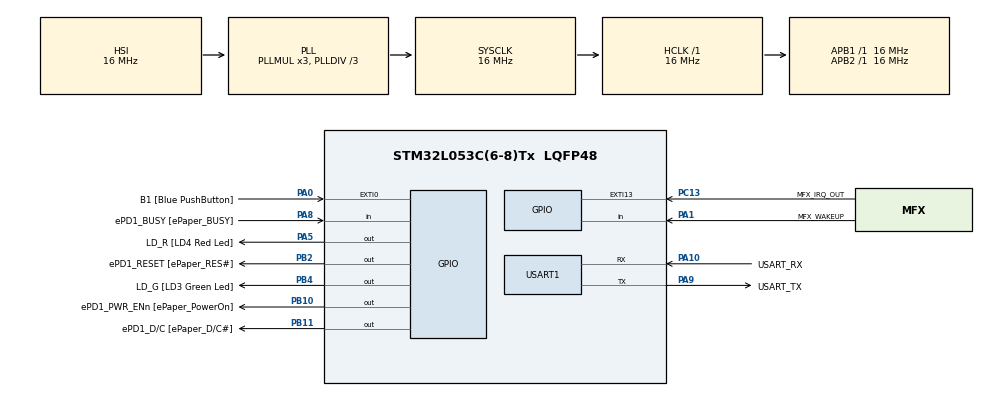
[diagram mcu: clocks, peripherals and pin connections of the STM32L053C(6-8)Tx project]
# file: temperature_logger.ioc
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Mcu.Family=STM32L0
Mcu.Name=STM32L053C(6-8)Tx
Mcu.Package=LQFP48
NVIC.RTC_IRQn=true\:0\:0\:false\:false\:true\:true
PA0.GPIO_Label=B1 [Blue PushButton]
PA0.GPIO_ModeDefaultEXTI=GPIO_MODE_EVT_RISING
PA0.GPIO_PuPd=GPIO_NOPULL
PA0.Signal=GPXTI0
PA1.GPIO_Label=MFX_WAKEUP
PA1.Signal=GPIO_Input
PA10.GPIO_Label=USART_RX
PA10.Mode=Asynchronous
PA10.Signal=USART1_RX
PA11.GPIO_Label=USB1_DM
PA11.Signal=USB_DM
PA12.GPIO_Label=USB1_DP
PA12.Signal=USB_DP
PA13.GPIO_Label=SWDIO
PA13.Signal=SYS_SWDIO
PA15.GPIO_Label=ePD1_CS [ePaper_CS\#]
PA15.GPIO_Mode=GPIO_MODE_AF_PP
PA15.GPIO_PuPd=GPIO_NOPULL
PA15.GPIO_Speed=GPIO_SPEED_FREQ_LOW
PA15.Signal=SPI1_NSS
PA2.Signal=TSC_G1_IO3
PA3.Signal=TSC_G1_IO4
PA5.GPIO_Label=LD_R [LD4 Red Led]
PA5.GPIO_ModeDefaultOutputPP=GPIO_MODE_OUTPUT_PP
PA5.GPIO_PuPd=GPIO_NOPULL
PA5.GPIO_Speed=GPIO_SPEED_FREQ_LOW
PA5.Signal=GPIO_Output
PA6.Signal=TSC_G2_IO3
PA7.Signal=TSC_G2_IO4
PA8.GPIO_Label=ePD1_BUSY [ePaper_BUSY]
PA8.GPIO_Mode=GPIO_MODE_INPUT
PA8.GPIO_PuPd=GPIO_NOPULL
PA8.Signal=GPIO_Input
PA9.GPIO_Label=USART_TX
PA9.Mode=Asynchronous
PA9.Signal=USART1_TX
PB0.Signal=TSC_G3_IO2
PB1.Signal=TSC_G3_IO3
PB10.GPIO_Label=ePD1_PWR_ENn [ePaper_PowerOn]
PB10.GPIO_ModeDefaultOutputPP=GPIO_MODE_OUTPUT_PP
PB10.GPIO_PuPd=GPIO_NOPULL
PB10.GPIO_Speed=GPIO_SPEED_FREQ_LOW
PB10.Signal=GPIO_Output
PB11.GPIO_Label=ePD1_D/C [ePaper_D/C\#]
PB11.GPIO_ModeDefaultOutputPP=GPIO_MODE_OUTPUT_PP
PB11.GPIO_PuPd=GPIO_NOPULL
PB11.GPIO_Speed=GPIO_SPEED_FREQ_LOW
PB11.Signal=GPIO_Output
PB12.GPIO_Label=NFC_NSS
PB12.Signal=SPI2_NSS
PB13.GPIO_Label=NFC_SCK
PB13.Signal=SPI2_SCK
PB14.GPIO_Label=NFC_MISO
PB14.Signal=SPI2_MISO
PB15.GPIO_Label=NFC_MOSI
PB15.Signal=SPI2_MOSI
PB2.GPIO_Label=ePD1_RESET [ePaper_RES\#]
PB2.GPIO_ModeDefaultOutputPP=GPIO_MODE_OUTPUT_PP
PB2.GPIO_PuPd=GPIO_NOPULL
PB2.GPIO_Speed=GPIO_SPEED_FREQ_LOW
PB2.Signal=GPIO_Output
PB3.GPIO_Label=ePD1_SCK [ePaper_SCK]
PB3.GPIO_Mode=GPIO_MODE_AF_PP
PB3.GPIO_PuPd=GPIO_NOPULL
PB3.GPIO_Speed=GPIO_SPEED_FREQ_LOW
PB3.Signal=SPI1_SCK
PB4.GPIO_Label=LD_G [LD3 Green Led]
PB4.GPIO_ModeDefaultOutputPP=GPIO_MODE_OUTPUT_PP
PB4.GPIO_PuPd=GPIO_NOPULL
PB4.GPIO_Speed=GPIO_SPEED_FREQ_LOW
PB4.Signal=GPIO_Output
PB5.GPIO_Label=ePD1_MOSI [ePaper_MOSI]
PB5.GPIO_Mode=GPIO_MODE_AF_PP
PB5.GPIO_PuPd=GPIO_NOPULL
PB5.GPIO_Speed=GPIO_SPEED_FREQ_LOW
PB5.Signal=SPI1_MOSI
PB8.GPIO_Label=MFX_I2C_SCL
PB8.Signal=I2C1_SCL
PB9.GPIO_Label=MFX_I2C_SDA
PB9.Signal=I2C1_SDA
PC13.GPIO_Label=MFX_IRQ_OUT
PC13.Signal=GPXTI13
PC14-OSC32_IN.GPIO_Label=PC14-OSC32_IN
PC14-OSC32_IN.Signal=RCC_OSC32_IN
PC15-OSC32_OUT.GPIO_Label=PC15-OSC32_OUT
PC15-OSC32_OUT.Signal=RCC_OSC32_OUT
PH0-OSC_IN.GPIO_Label=MCO
PH0-OSC_IN.Signal=RCC_OSC_IN
ProjectManager.HeapSize=0x200
ProjectManager.StackSize=0x400
ProjectManager.TargetToolchain=SW4STM32
RCC.AHBFreq_Value=16000000
RCC.APB1Freq_Value=16000000
RCC.APB1TimFreq_Value=16000000
RCC.APB2Freq_Value=16000000
RCC.APB2TimFreq_Value=16000000
RCC.HCLKFreq_Value=16000000
RCC.HSE_VALUE=8000000
RCC.HSI16_VALUE=16000000
RCC.HSI48MClockSelection=RCC_USBCLKSOURCE_HSI48
RCC.HSI48_VALUE=48000000
RCC.HSI_VALUE=16000000
RCC.LSE_VALUE=32768
RCC.MSI_VALUE=2097000
RCC.PLLDIV=RCC_PLLDIV_3
RCC.RTCClockSelection=RCC_RTCCLKSOURCE_LSI
RCC.RTCClockSelectionVirtual=RCC_RTCCLKSOURCE_LSE
RCC.SYSCLKFreq_VALUE=16000000
RCC.SYSCLKSource=RCC_SYSCLKSOURCE_PLLCLK
RCC.VCOOutputFreq_Value=48000000
RTC.Alarm-Alarm\ A=RTC_ALARM_A
RTC.AlarmMaskDateWeekDay-Alarm\ A=RTC_ALARMMASK_DATEWEEKDAY
RTC.AsynchPrediv=100
RTC.Date=26
RTC.Format=RTC_FORMAT_BIN
RTC.Hours=11
RTC.Minutes=50
RTC.Month=RTC_MONTH_NOVEMBER
RTC.SynchPrediv=370
RTC.WeekDay=RTC_WEEKDAY_SUNDAY
RTC.Year=17
USART1.VirtualMode-Asynchronous=VM_ASYNC
USART1.WordLength=WORDLENGTH_8B
VP_RTC_VS_RTC_Activate.Mode=RTC_Enabled
VP_RTC_VS_RTC_Alarm_A_Intern.Mode=Alarm A
VP_RTC_VS_RTC_Calendar.Mode=RTC_Calendar
board=STM32L0538-DISCO

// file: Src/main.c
/**
  ******************************************************************************
  * File Name          : main.c
  * Description        : Main program body
  ******************************************************************************
  ** This notice applies to any and all portions of this file
  * that are not between comment pairs USER CODE BEGIN and
  * USER CODE END. Other portions of this file, whether
  * inserted by the user or by software development tools
  * are owned by their respective copyright owners.
  *
  * COPYRIGHT(c) 2017 STMicroelectronics
  *
  * Redistribution and use in source and binary forms, with or without modification,
  * are permitted provided that the following conditions are met:
  *   1. Redistributions of source code must retain the above copyright notice,
  *      this list of conditions and the following disclaimer.
  *   2. Redistributions in binary form must reproduce the above copyright notice,
  *      this list of conditions and the following disclaimer in the documentation
  *      and/or other materials provided with the distribution.
  *   3. Neither the name of STMicroelectronics nor the names of its contributors
  *      may be used to endorse or promote products derived from this software
  *      without specific prior written permission.
  *
  * THIS SOFTWARE IS PROVIDED BY THE COPYRIGHT HOLDERS AND CONTRIBUTORS "AS IS"
  * AND ANY EXPRESS OR IMPLIED WARRANTIES, INCLUDING, BUT NOT LIMITED TO, THE
  * IMPLIED WARRANTIES OF MERCHANTABILITY AND FITNESS FOR A PARTICULAR PURPOSE ARE
  * DISCLAIMED. IN NO EVENT SHALL THE COPYRIGHT HOLDER OR CONTRIBUTORS BE LIABLE
  * FOR ANY DIRECT, INDIRECT, INCIDENTAL, SPECIAL, EXEMPLARY, OR CONSEQUENTIAL
  * DAMAGES (INCLUDING, BUT NOT LIMITED TO, PROCUREMENT OF SUBSTITUTE GOODS OR
  * SERVICES; LOSS OF USE, DATA, OR PROFITS; OR BUSINESS INTERRUPTION) HOWEVER
  * CAUSED AND ON ANY THEORY OF LIABILITY, WHETHER IN CONTRACT, STRICT LIABILITY,
  * OR TORT (INCLUDING NEGLIGENCE OR OTHERWISE) ARISING IN ANY WAY OUT OF THE USE
  * OF THIS SOFTWARE, EVEN IF ADVISED OF THE POSSIBILITY OF SUCH DAMAGE.
  *
  ******************************************************************************
  */

#include "main.h"
#include "stm32l0xx_hal.h"

/* USER CODE BEGIN Includes */
#include "internal_clock_mgt.h"
/* USER CODE END Includes */

RTC_HandleTypeDef hrtc;

UART_HandleTypeDef huart1;
/* USER CODE BEGIN PV */
/* Private variables ---------------------------------------------------------*/

RTC_AlarmTypeDef sAlarm;
RTC_TimeTypeDef current_time;
RTC_DateTypeDef current_date;

/* USER CODE END PV */

void SystemClock_Config(void);
static void MX_GPIO_Init(void);
static void MX_USART1_UART_Init(void);
static void MX_RTC_Init(void);

/* USER CODE BEGIN PFP */
/* Private function prototypes -----------------------------------------------*/

/* USER CODE END PFP */

int main(void)
{

  /* MCU Configuration----------------------------------------------------------*/

  /* Reset of all peripherals, Initializes the Flash interface and the Systick. */
  HAL_Init();

  /* Configure the system clock */
  SystemClock_Config();

  /* Initialize all configured peripherals */
  MX_GPIO_Init();
  MX_USART1_UART_Init();
  MX_RTC_Init();

  /* USER CODE BEGIN 2 */

  show_time();
  set_alarm();
  /* USER CODE END 2 */

  /* Infinite loop */
  while (1)
  {

  }

}

/** System Clock Configuration
*/
void SystemClock_Config(void)
{

  RCC_OscInitTypeDef RCC_OscInitStruct;
  RCC_ClkInitTypeDef RCC_ClkInitStruct;
  RCC_PeriphCLKInitTypeDef PeriphClkInit;

    /**Configure the main internal regulator output voltage
    */
  __HAL_PWR_VOLTAGESCALING_CONFIG(PWR_REGULATOR_VOLTAGE_SCALE1);

    /**Initializes the CPU, AHB and APB busses clocks
    */
  RCC_OscInitStruct.OscillatorType = RCC_OSCILLATORTYPE_HSI|RCC_OSCILLATORTYPE_LSI;
  RCC_OscInitStruct.HSIState = RCC_HSI_ON;
  RCC_OscInitStruct.HSICalibrationValue = 16;
  RCC_OscInitStruct.LSIState = RCC_LSI_ON;
  RCC_OscInitStruct.PLL.PLLState = RCC_PLL_ON;
  RCC_OscInitStruct.PLL.PLLSource = RCC_PLLSOURCE_HSI;
  RCC_OscInitStruct.PLL.PLLMUL = RCC_PLLMUL_3;
  RCC_OscInitStruct.PLL.PLLDIV = RCC_PLLDIV_3;
  if (HAL_RCC_OscConfig(&RCC_OscInitStruct) != HAL_OK)
  {
    _Error_Handler(__FILE__, __LINE__);
  }

    /**Initializes the CPU, AHB and APB busses clocks
    */
  RCC_ClkInitStruct.ClockType = RCC_CLOCKTYPE_HCLK|RCC_CLOCKTYPE_SYSCLK
                              |RCC_CLOCKTYPE_PCLK1|RCC_CLOCKTYPE_PCLK2;
  RCC_ClkInitStruct.SYSCLKSource = RCC_SYSCLKSOURCE_PLLCLK;
  RCC_ClkInitStruct.AHBCLKDivider = RCC_SYSCLK_DIV1;
  RCC_ClkInitStruct.APB1CLKDivider = RCC_HCLK_DIV1;
  RCC_ClkInitStruct.APB2CLKDivider = RCC_HCLK_DIV1;

  if (HAL_RCC_ClockConfig(&RCC_ClkInitStruct, FLASH_LATENCY_0) != HAL_OK)
  {
    _Error_Handler(__FILE__, __LINE__);
  }

  PeriphClkInit.PeriphClockSelection = RCC_PERIPHCLK_USART1|RCC_PERIPHCLK_RTC;
  PeriphClkInit.Usart1ClockSelection = RCC_USART1CLKSOURCE_PCLK2;
  PeriphClkInit.RTCClockSelection = RCC_RTCCLKSOURCE_LSI;
  if (HAL_RCCEx_PeriphCLKConfig(&PeriphClkInit) != HAL_OK)
  {
    _Error_Handler(__FILE__, __LINE__);
  }

    /**Configure the Systick interrupt time
    */
  HAL_SYSTICK_Config(HAL_RCC_GetHCLKFreq()/1000);

    /**Configure the Systick
    */
  HAL_SYSTICK_CLKSourceConfig(SYSTICK_CLKSOURCE_HCLK);

  /* SysTick_IRQn interrupt configuration */
  HAL_NVIC_SetPriority(SysTick_IRQn, 0, 0);
}

/* RTC init function */
static void MX_RTC_Init(void)
{

  RTC_TimeTypeDef sTime;
  RTC_DateTypeDef sDate;
  RTC_AlarmTypeDef sAlarm;

    /**Initialize RTC Only
    */
  hrtc.Instance = RTC;
  hrtc.Init.HourFormat = RTC_HOURFORMAT_24;
  hrtc.Init.AsynchPrediv = 100;
  hrtc.Init.SynchPrediv = 370;
  hrtc.Init.OutPut = RTC_OUTPUT_DISABLE;
  hrtc.Init.OutPutRemap = RTC_OUTPUT_REMAP_NONE;
  hrtc.Init.OutPutPolarity = RTC_OUTPUT_POLARITY_HIGH;
  hrtc.Init.OutPutType = RTC_OUTPUT_TYPE_OPENDRAIN;
  if (HAL_RTC_Init(&hrtc) != HAL_OK)
  {
    _Error_Handler(__FILE__, __LINE__);
  }

    /**Initialize RTC and set the Time and Date
    */
  if(HAL_RTCEx_BKUPRead(&hrtc, RTC_BKP_DR0) != 0x32F2){
  sTime.Hours = 11;
  sTime.Minutes = 50;
  sTime.Seconds = 0;
  sTime.DayLightSaving = RTC_DAYLIGHTSAVING_NONE;
  sTime.StoreOperation = RTC_STOREOPERATION_RESET;
  if (HAL_RTC_SetTime(&hrtc, &sTime, RTC_FORMAT_BIN) != HAL_OK)
  {
    _Error_Handler(__FILE__, __LINE__);
  }

  sDate.WeekDay = RTC_WEEKDAY_SUNDAY;
  sDate.Month = RTC_MONTH_NOVEMBER;
  sDate.Date = 26;
  sDate.Year = 17;

  if (HAL_RTC_SetDate(&hrtc, &sDate, RTC_FORMAT_BIN) != HAL_OK)
  {
    _Error_Handler(__FILE__, __LINE__);
  }

    HAL_RTCEx_BKUPWrite(&hrtc,RTC_BKP_DR0,0x32F2);
  }
    /**Enable the Alarm A
    */
  sAlarm.AlarmTime.Hours = 0;
  sAlarm.AlarmTime.Minutes = 0;
  sAlarm.AlarmTime.Seconds = 0;
  sAlarm.AlarmTime.SubSeconds = 0;
  sAlarm.AlarmTime.DayLightSaving = RTC_DAYLIGHTSAVING_NONE;
  sAlarm.AlarmTime.StoreOperation = RTC_STOREOPERATION_RESET;
  sAlarm.AlarmMask = RTC_ALARMMASK_DATEWEEKDAY;
  sAlarm.AlarmSubSecondMask = RTC_ALARMSUBSECONDMASK_ALL;
  sAlarm.AlarmDateWeekDaySel = RTC_ALARMDATEWEEKDAYSEL_DATE;
  sAlarm.AlarmDateWeekDay = 1;
  sAlarm.Alarm = RTC_ALARM_A;
  if (HAL_RTC_SetAlarm_IT(&hrtc, &sAlarm, RTC_FORMAT_BIN) != HAL_OK)
  {
    _Error_Handler(__FILE__, __LINE__);
  }

}

/* USART1 init function */
static void MX_USART1_UART_Init(void)
{

  huart1.Instance = USART1;
  huart1.Init.BaudRate = 115200;
  huart1.Init.WordLength = UART_WORDLENGTH_8B;
  huart1.Init.StopBits = UART_STOPBITS_1;
  huart1.Init.Parity = UART_PARITY_NONE;
  huart1.Init.Mode = UART_MODE_TX_RX;
  huart1.Init.HwFlowCtl = UART_HWCONTROL_NONE;
  huart1.Init.OverSampling = UART_OVERSAMPLING_16;
  huart1.Init.OneBitSampling = UART_ONE_BIT_SAMPLE_DISABLE;
  huart1.AdvancedInit.AdvFeatureInit = UART_ADVFEATURE_NO_INIT;
  if (HAL_UART_Init(&huart1) != HAL_OK)
  {
    _Error_Handler(__FILE__, __LINE__);
  }

}

/** Configure pins as
        * Analog
        * Input
        * Output
        * EVENT_OUT
        * EXTI
     PA2   ------> TSC_G1_IO3
     PA3   ------> TSC_G1_IO4
     PA6   ------> TSC_G2_IO3
     PA7   ------> TSC_G2_IO4
     PB0   ------> TSC_G3_IO2
     PB1   ------> TSC_G3_IO3
     PB12   ------> SPI2_NSS
     PB13   ------> SPI2_SCK
     PB14   ------> SPI2_MISO
     PB15   ------> SPI2_MOSI
     PA15   ------> SPI1_NSS
     PB3   ------> SPI1_SCK
     PB5   ------> SPI1_MOSI
     PB8   ------> I2C1_SCL
     PB9   ------> I2C1_SDA
*/
static void MX_GPIO_Init(void)
{

  GPIO_InitTypeDef GPIO_InitStruct;

  /* GPIO Ports Clock Enable */
  __HAL_RCC_GPIOC_CLK_ENABLE();
  __HAL_RCC_GPIOH_CLK_ENABLE();
  __HAL_RCC_GPIOA_CLK_ENABLE();
  __HAL_RCC_GPIOB_CLK_ENABLE();

  /*Configure GPIO pin Output Level */
  HAL_GPIO_WritePin(LD_R_GPIO_Port, LD_R_Pin, GPIO_PIN_RESET);

  /*Configure GPIO pin Output Level */
  HAL_GPIO_WritePin(GPIOB, ePD1_RESET_Pin|ePD1_PWR_ENn_Pin|ePD1_D_C_Pin|LD_G_Pin, GPIO_PIN_RESET);

  /*Configure GPIO pin : MFX_IRQ_OUT_Pin */
  GPIO_InitStruct.Pin = MFX_IRQ_OUT_Pin;
  GPIO_InitStruct.Mode = GPIO_MODE_IT_RISING;
  GPIO_InitStruct.Pull = GPIO_NOPULL;
  HAL_GPIO_Init(MFX_IRQ_OUT_GPIO_Port, &GPIO_InitStruct);

  /*Configure GPIO pin : B1_Pin */
  GPIO_InitStruct.Pin = B1_Pin;
  GPIO_InitStruct.Mode = GPIO_MODE_EVT_RISING;
  GPIO_InitStruct.Pull = GPIO_NOPULL;
  HAL_GPIO_Init(B1_GPIO_Port, &GPIO_InitStruct);

  /*Configure GPIO pins : MFX_WAKEUP_Pin ePD1_BUSY_Pin */
  GPIO_InitStruct.Pin = MFX_WAKEUP_Pin|ePD1_BUSY_Pin;
  GPIO_InitStruct.Mode = GPIO_MODE_INPUT;
  GPIO_InitStruct.Pull = GPIO_NOPULL;
  HAL_GPIO_Init(GPIOA, &GPIO_InitStruct);

  /*Configure GPIO pins : PA2 PA3 PA6 PA7 */
  GPIO_InitStruct.Pin = GPIO_PIN_2|GPIO_PIN_3|GPIO_PIN_6|GPIO_PIN_7;
  GPIO_InitStruct.Mode = GPIO_MODE_AF_PP;
  GPIO_InitStruct.Pull = GPIO_NOPULL;
  GPIO_InitStruct.Speed = GPIO_SPEED_FREQ_LOW;
  GPIO_InitStruct.Alternate = GPIO_AF3_TSC;
  HAL_GPIO_Init(GPIOA, &GPIO_InitStruct);

  /*Configure GPIO pin : LD_R_Pin */
  GPIO_InitStruct.Pin = LD_R_Pin;
  GPIO_InitStruct.Mode = GPIO_MODE_OUTPUT_PP;
  GPIO_InitStruct.Pull = GPIO_NOPULL;
  GPIO_InitStruct.Speed = GPIO_SPEED_FREQ_LOW;
  HAL_GPIO_Init(LD_R_GPIO_Port, &GPIO_InitStruct);

  /*Configure GPIO pins : PB0 PB1 */
  GPIO_InitStruct.Pin = GPIO_PIN_0|GPIO_PIN_1;
  GPIO_InitStruct.Mode = GPIO_MODE_AF_PP;
  GPIO_InitStruct.Pull = GPIO_NOPULL;
  GPIO_InitStruct.Speed = GPIO_SPEED_FREQ_LOW;
  GPIO_InitStruct.Alternate = GPIO_AF3_TSC;
  HAL_GPIO_Init(GPIOB, &GPIO_InitStruct);

  /*Configure GPIO pins : ePD1_RESET_Pin ePD1_PWR_ENn_Pin ePD1_D_C_Pin LD_G_Pin */
  GPIO_InitStruct.Pin = ePD1_RESET_Pin|ePD1_PWR_ENn_Pin|ePD1_D_C_Pin|LD_G_Pin;
  GPIO_InitStruct.Mode = GPIO_MODE_OUTPUT_PP;
  GPIO_InitStruct.Pull = GPIO_NOPULL;
  GPIO_InitStruct.Speed = GPIO_SPEED_FREQ_LOW;
  HAL_GPIO_Init(GPIOB, &GPIO_InitStruct);

  /*Configure GPIO pins : NFC_NSS_Pin NFC_SCK_Pin NFC_MISO_Pin NFC_MOSI_Pin */
  GPIO_InitStruct.Pin = NFC_NSS_Pin|NFC_SCK_Pin|NFC_MISO_Pin|NFC_MOSI_Pin;
  GPIO_InitStruct.Mode = GPIO_MODE_AF_PP;
  GPIO_InitStruct.Pull = GPIO_NOPULL;
  GPIO_InitStruct.Speed = GPIO_SPEED_FREQ_VERY_HIGH;
  GPIO_InitStruct.Alternate = GPIO_AF0_SPI2;
  HAL_GPIO_Init(GPIOB, &GPIO_InitStruct);

  /*Configure GPIO pin : ePD1_CS_Pin */
  GPIO_InitStruct.Pin = ePD1_CS_Pin;
  GPIO_InitStruct.Mode = GPIO_MODE_AF_PP;
  GPIO_InitStruct.Pull = GPIO_NOPULL;
  GPIO_InitStruct.Speed = GPIO_SPEED_FREQ_LOW;
  GPIO_InitStruct.Alternate = GPIO_AF0_SPI1;
  HAL_GPIO_Init(ePD1_CS_GPIO_Port, &GPIO_InitStruct);

  /*Configure GPIO pins : ePD1_SCK_Pin ePD1_MOSI_Pin */
  GPIO_InitStruct.Pin = ePD1_SCK_Pin|ePD1_MOSI_Pin;
  GPIO_InitStruct.Mode = GPIO_MODE_AF_PP;
  GPIO_InitStruct.Pull = GPIO_NOPULL;
  GPIO_InitStruct.Speed = GPIO_SPEED_FREQ_LOW;
  GPIO_InitStruct.Alternate = GPIO_AF0_SPI1;
  HAL_GPIO_Init(GPIOB, &GPIO_InitStruct);

  /*Configure GPIO pins : MFX_I2C_SCL_Pin MFX_I2C_SDA_Pin */
  GPIO_InitStruct.Pin = MFX_I2C_SCL_Pin|MFX_I2C_SDA_Pin;
  GPIO_InitStruct.Mode = GPIO_MODE_AF_OD;
  GPIO_InitStruct.Pull = GPIO_PULLUP;
  GPIO_InitStruct.Speed = GPIO_SPEED_FREQ_VERY_HIGH;
  GPIO_InitStruct.Alternate = GPIO_AF4_I2C1;
  HAL_GPIO_Init(GPIOB, &GPIO_InitStruct);

}

void _Error_Handler(char * file, int line)
{
  /* USER CODE BEGIN Error_Handler_Debug */
  /* User can add his own implementation to report the HAL error return state */
  while(1)
  {
	  HAL_Delay(250);

	  HAL_GPIO_TogglePin(LD_R_GPIO_Port, LD_R_Pin);
  }
  /* USER CODE END Error_Handler_Debug */
}

/************************ (C) COPYRIGHT STMicroelectronics *****END OF FILE****/
